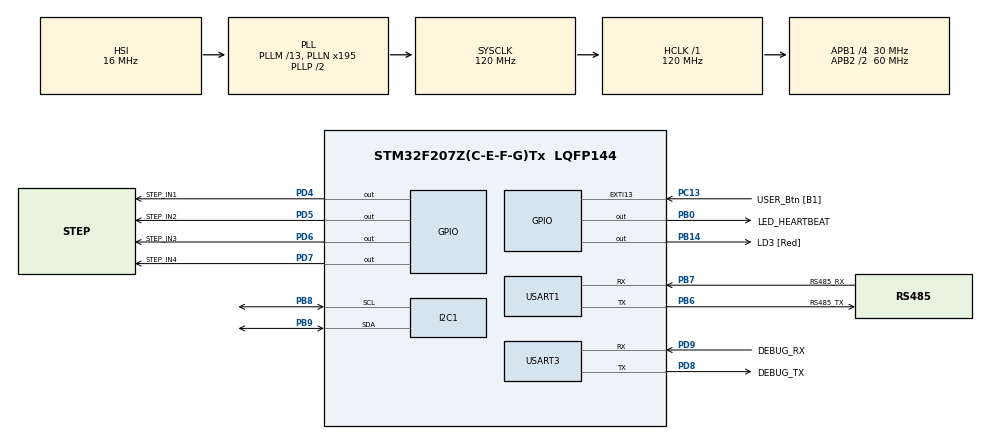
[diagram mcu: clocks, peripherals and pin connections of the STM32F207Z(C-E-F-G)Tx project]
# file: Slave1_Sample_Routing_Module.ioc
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Mcu.Family=STM32F2
Mcu.Name=STM32F207Z(C-E-F-G)Tx
Mcu.Package=LQFP144
NVIC.PriorityGroup=NVIC_PRIORITYGROUP_4
PA13.GPIO_Label=TMS
PA13.Mode=Serial_Wire
PA13.Signal=SYS_JTMS-SWDIO
PA14.GPIO_Label=TCK
PA14.Mode=Serial_Wire
PA14.Signal=SYS_JTCK-SWCLK
PB0.GPIO_Label=LED_HEARTBEAT
PB0.Signal=GPIO_Output
PB14.GPIO_Label=LD3 [Red]
PB14.Signal=GPIO_Output
PB3.GPIO_Label=SWO
PB3.Signal=SYS_JTDO-SWO
PB6.GPIO_Label=RS485_TX
PB6.Mode=Asynchronous
PB6.Signal=USART1_TX
PB7.GPIO_Label=RS485_RX
PB7.Mode=Asynchronous
PB7.Signal=USART1_RX
PB8.Mode=I2C
PB8.Signal=I2C1_SCL
PB9.Mode=I2C
PB9.Signal=I2C1_SDA
PC13.GPIO_Label=USER_Btn [B1]
PC13.Signal=GPXTI13
PC14-OSC32_IN.Signal=RCC_OSC32_IN
PC15-OSC32_OUT.Signal=RCC_OSC32_OUT
PD4.GPIO_Label=STEP_IN1
PD4.Signal=GPIO_Output
PD5.GPIO_Label=STEP_IN2
PD5.Signal=GPIO_Output
PD6.GPIO_Label=STEP_IN3
PD6.Signal=GPIO_Output
PD7.GPIO_Label=STEP_IN4
PD7.Signal=GPIO_Output
PD8.GPIO_Label=DEBUG_TX
PD8.Mode=Asynchronous
PD8.Signal=USART3_TX
PD9.GPIO_Label=DEBUG_RX
PD9.Mode=Asynchronous
PD9.Signal=USART3_RX
PH0-OSC_IN.GPIO_Label=MCO [STM32F103CBT6_PA8]
PH0-OSC_IN.Signal=RCC_OSC_IN
PH1-OSC_OUT.Signal=RCC_OSC_OUT
ProjectManager.HeapSize=0x200
ProjectManager.StackSize=0x400
ProjectManager.TargetToolchain=STM32CubeIDE
RCC.48MHZClocksFreq_Value=48000000
RCC.AHBFreq_Value=120000000
RCC.APB1CLKDivider=RCC_HCLK_DIV4
RCC.APB1Freq_Value=30000000
RCC.APB1TimFreq_Value=60000000
RCC.APB2CLKDivider=RCC_HCLK_DIV2
RCC.APB2Freq_Value=60000000
RCC.APB2TimFreq_Value=120000000
RCC.CortexFreq_Value=120000000
RCC.HCLKFreq_Value=120000000
RCC.HSE_VALUE=8000000
RCC.HSI_VALUE=16000000
RCC.LSE_VALUE=32768
RCC.PLLM=13
RCC.PLLMUL=RCC_PLL_MUL9
RCC.PLLN=195
RCC.PLLQ=5
RCC.PRESCALERUSB=RCC_USBCLKSOURCE_PLL_DIV1_5
RCC.SYSCLKFreq_VALUE=120000000
RCC.SYSCLKSource=RCC_SYSCLKSOURCE_PLLCLK
RCC.SYSCLKSourceVirtual=RCC_SYSCLKSOURCE_PLLCLK
RCC.USBFreq_Value=48000000
RCC.VCOOutputFreq_Value=240000000
USART1.VirtualMode=VM_ASYNC
USART3.VirtualMode=VM_ASYNC
board=NUCLEO-F207ZG

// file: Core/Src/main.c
/* USER CODE BEGIN Header */
/**
  ******************************************************************************
  * @file           : main.c
  * @brief          : Main program body
  ******************************************************************************
  * @attention
  *
  * Copyright (c) 2026 STMicroelectronics.
  * All rights reserved.
  *
  * This software is licensed under terms that can be found in the LICENSE file
  * in the root directory of this software component.
  * If no LICENSE file comes with this software, it is provided AS-IS.
  *
  ******************************************************************************
  */
/* USER CODE END Header */
#include "main.h"
#include "i2c.h"
#include "usart.h"
#include "gpio.h"

/* USER CODE BEGIN Includes */
#include "app_main.h"
#include "uart_if.h"
/* USER CODE END Includes */

void SystemClock_Config(void);

/* USER CODE BEGIN 0 */
void HAL_UART_RxCpltCallback(UART_HandleTypeDef *huart)
{
  uart_if_handle_rx_cplt(huart);
}
/* USER CODE END 0 */

int main(void)
{

  /* MCU Configuration--------------------------------------------------------*/

  /* Reset of all peripherals, Initializes the Flash interface and the Systick. */
  HAL_Init();

  /* Configure the system clock */
  SystemClock_Config();

  /* Initialize all configured peripherals */
  MX_GPIO_Init();
  MX_USART3_UART_Init();
  MX_I2C1_Init();
  MX_USART1_UART_Init();
  /* USER CODE BEGIN 2 */
  app_main_init();
  /* USER CODE END 2 */

  /* Infinite loop */
  /* USER CODE BEGIN WHILE */
  while (1)
  {
    app_main_run();
    /* USER CODE END WHILE */

  }
}

void SystemClock_Config(void)
{
  RCC_OscInitTypeDef RCC_OscInitStruct = {0};
  RCC_ClkInitTypeDef RCC_ClkInitStruct = {0};

  /** Initializes the RCC Oscillators according to the specified parameters
  * in the RCC_OscInitTypeDef structure.
  */
  RCC_OscInitStruct.OscillatorType = RCC_OSCILLATORTYPE_HSI;
  RCC_OscInitStruct.HSIState = RCC_HSI_ON;
  RCC_OscInitStruct.HSICalibrationValue = RCC_HSICALIBRATION_DEFAULT;
  RCC_OscInitStruct.PLL.PLLState = RCC_PLL_ON;
  RCC_OscInitStruct.PLL.PLLSource = RCC_PLLSOURCE_HSI;
  RCC_OscInitStruct.PLL.PLLM = 13;
  RCC_OscInitStruct.PLL.PLLN = 195;
  RCC_OscInitStruct.PLL.PLLP = RCC_PLLP_DIV2;
  RCC_OscInitStruct.PLL.PLLQ = 5;
  if (HAL_RCC_OscConfig(&RCC_OscInitStruct) != HAL_OK)
  {
    Error_Handler();
  }

  /** Initializes the CPU, AHB and APB buses clocks
  */
  RCC_ClkInitStruct.ClockType = RCC_CLOCKTYPE_HCLK|RCC_CLOCKTYPE_SYSCLK
                              |RCC_CLOCKTYPE_PCLK1|RCC_CLOCKTYPE_PCLK2;
  RCC_ClkInitStruct.SYSCLKSource = RCC_SYSCLKSOURCE_PLLCLK;
  RCC_ClkInitStruct.AHBCLKDivider = RCC_SYSCLK_DIV1;
  RCC_ClkInitStruct.APB1CLKDivider = RCC_HCLK_DIV4;
  RCC_ClkInitStruct.APB2CLKDivider = RCC_HCLK_DIV2;

  if (HAL_RCC_ClockConfig(&RCC_ClkInitStruct, FLASH_LATENCY_3) != HAL_OK)
  {
    Error_Handler();
  }
}

void Error_Handler(void)
{
  __disable_irq();
  while (1)
  {
  }
}
